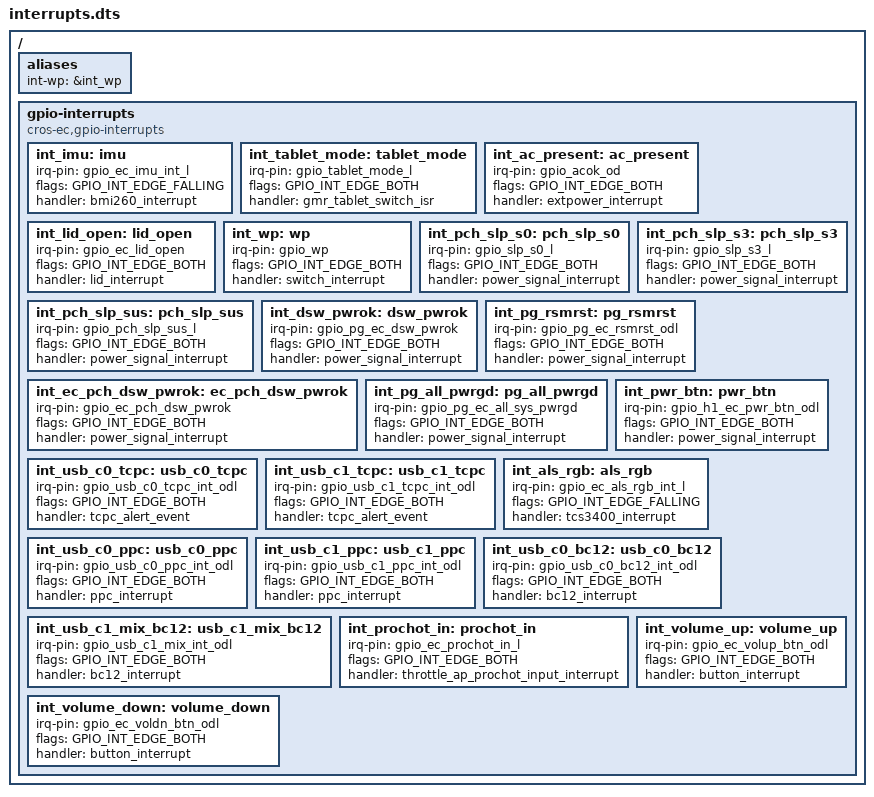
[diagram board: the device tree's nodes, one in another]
/* Copyright 2022 The Chromium OS Authors. All rights reserved.
 * Use of this source code is governed by a BSD-style license that can be
 * found in the LICENSE file.
 */

/ {
	aliases {
		int-wp = &int_wp;
	};

	gpio-interrupts {
		compatible = "cros-ec,gpio-interrupts";

		int_imu: imu {
			irq-pin = <&gpio_ec_imu_int_l>;
			flags = <GPIO_INT_EDGE_FALLING>;
			handler = "bmi260_interrupt";
		};
		int_tablet_mode: tablet_mode {
			irq-pin = <&gpio_tablet_mode_l>;
			flags = <GPIO_INT_EDGE_BOTH>;
			handler = "gmr_tablet_switch_isr";
		};
		int_ac_present: ac_present {
			irq-pin = <&XG>;
			flags = <GPIO_INT_EDGE_BOTH>;
			handler = "XH";
		};
		int_ac_present: ac_present {
			irq-pin = <&gpio_acok_od>;
			flags = <GPIO_INT_EDGE_BOTH>;
			handler = "extpower_interrupt";
		};
		int_lid_open: lid_open {
			irq-pin = <&gpio_ec_lid_open>;
			flags = <GPIO_INT_EDGE_BOTH>;
			handler = "lid_interrupt";
		};
		int_wp: wp {
			irq-pin = <&gpio_wp>;
			flags = <GPIO_INT_EDGE_BOTH>;
			handler = "switch_interrupt";
		};
		int_pch_slp_s0: pch_slp_s0 {
			irq-pin = <&gpio_slp_s0_l>;
			flags = <GPIO_INT_EDGE_BOTH>;
			handler = "power_signal_interrupt";
		};
		int_pch_slp_s3: pch_slp_s3 {
			irq-pin = <&gpio_slp_s3_l>;
			flags = <GPIO_INT_EDGE_BOTH>;
			handler = "power_signal_interrupt";
		};
		int_pch_slp_sus: pch_slp_sus {
			irq-pin = <&gpio_pch_slp_sus_l>;
			flags = <GPIO_INT_EDGE_BOTH>;
			handler = "power_signal_interrupt";
		};
		int_dsw_pwrok: dsw_pwrok {
			irq-pin = <&gpio_pg_ec_dsw_pwrok>;
			flags = <GPIO_INT_EDGE_BOTH>;
			handler = "power_signal_interrupt";
		};
		int_pg_rsmrst: pg_rsmrst {
			irq-pin = <&gpio_pg_ec_rsmrst_odl>;
			flags = <GPIO_INT_EDGE_BOTH>;
			handler = "power_signal_interrupt";
		};
		int_ec_pch_dsw_pwrok: ec_pch_dsw_pwrok {
			irq-pin = <&gpio_ec_pch_dsw_pwrok>;
			flags = <GPIO_INT_EDGE_BOTH>;
			handler = "power_signal_interrupt";
		};
		int_pg_all_pwrgd: pg_all_pwrgd {
			irq-pin = <&gpio_pg_ec_all_sys_pwrgd>;
			flags = <GPIO_INT_EDGE_BOTH>;
			handler = "power_signal_interrupt";
		};
		int_pwr_btn: pwr_btn {
			irq-pin = <&gpio_h1_ec_pwr_btn_odl>;
			flags = <GPIO_INT_EDGE_BOTH>;
			handler = "power_signal_interrupt";
		};
		int_usb_c0_tcpc: usb_c0_tcpc {
			irq-pin = <&gpio_usb_c0_tcpc_int_odl>;
			flags = <GPIO_INT_EDGE_BOTH>;
			handler = "tcpc_alert_event";
		};
		int_usb_c1_tcpc: usb_c1_tcpc {
			irq-pin = <&gpio_usb_c1_tcpc_int_odl>;
			flags = <GPIO_INT_EDGE_BOTH>;
			handler = "tcpc_alert_event";
		};
		int_als_rgb: als_rgb {
			irq-pin = <&gpio_ec_als_rgb_int_l>;
			flags = <GPIO_INT_EDGE_FALLING>;
			handler = "tcs3400_interrupt";
		};
		int_usb_c0_ppc: usb_c0_ppc {
			irq-pin = <&gpio_usb_c0_ppc_int_odl>;
			flags = <GPIO_INT_EDGE_BOTH>;
			handler = "ppc_interrupt";
		};
		int_usb_c1_ppc: usb_c1_ppc {
			irq-pin = <&gpio_usb_c1_ppc_int_odl>;
			flags = <GPIO_INT_EDGE_BOTH>;
			handler = "ppc_interrupt";
		};
		int_usb_c0_bc12: usb_c0_bc12 {
			irq-pin = <&gpio_usb_c0_bc12_int_odl>;
			flags = <GPIO_INT_EDGE_BOTH>;
			handler = "bc12_interrupt";
		};
		int_usb_c1_mix_bc12: usb_c1_mix_bc12 {
			irq-pin = <&gpio_usb_c1_mix_int_odl>;
			flags = <GPIO_INT_EDGE_BOTH>;
			handler = "bc12_interrupt";
		};
		int_prochot_in: prochot_in {
			irq-pin = <&gpio_ec_prochot_in_l>;
			flags = <GPIO_INT_EDGE_BOTH>;
			handler = "throttle_ap_prochot_input_interrupt";
		};
		int_volume_up: volume_up {
			irq-pin = <&gpio_ec_volup_btn_odl>;
			flags = <GPIO_INT_EDGE_BOTH>;
			handler = "button_interrupt";
		};
		int_volume_down: volume_down {
			irq-pin = <&gpio_ec_voldn_btn_odl>;
			flags = <GPIO_INT_EDGE_BOTH>;
			handler = "button_interrupt";
		};
	};
};
